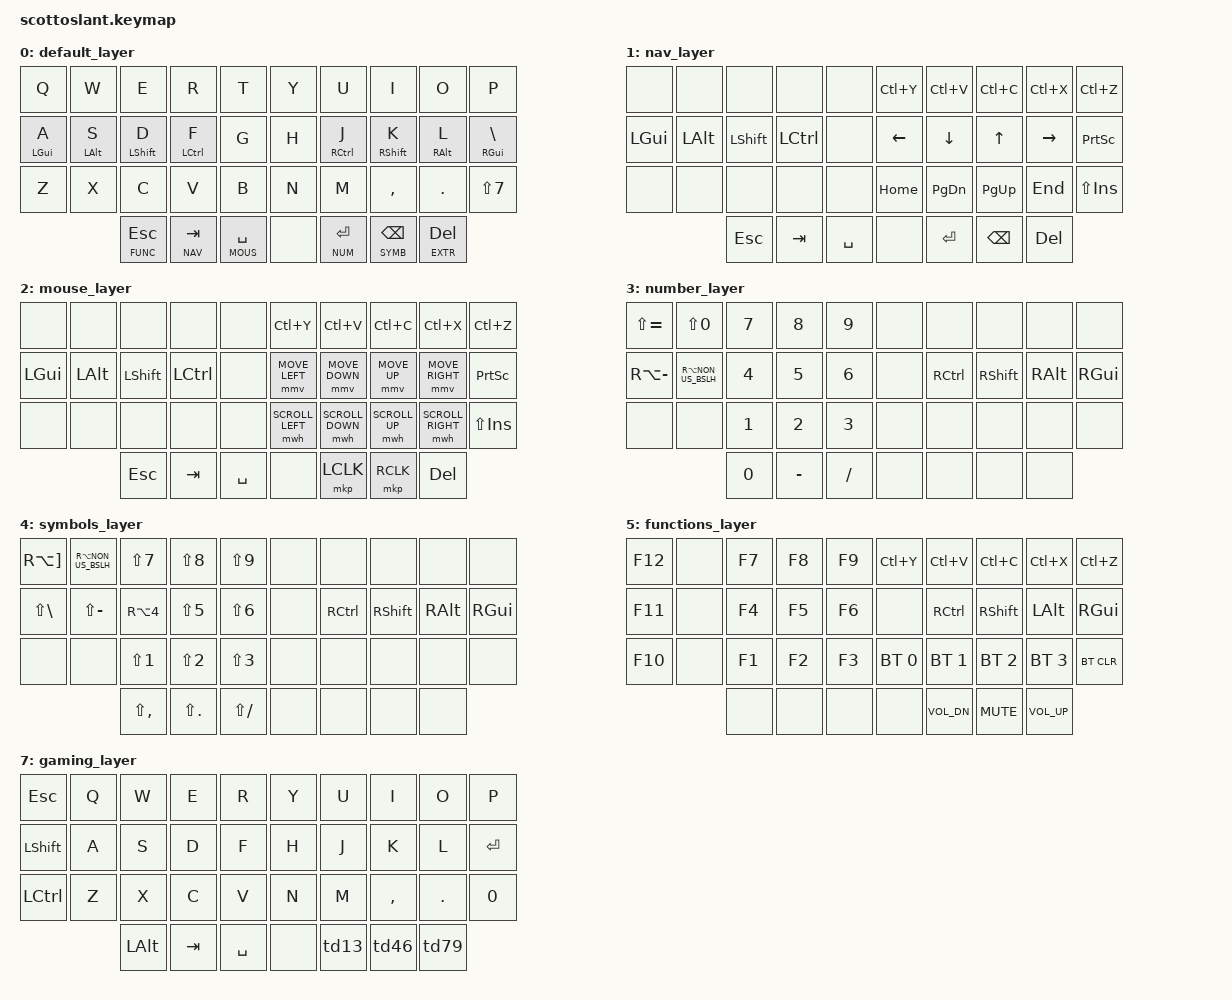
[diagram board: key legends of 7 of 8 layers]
#include <behaviors.dtsi>
#include <dt-bindings/zmk/keys.h>
#include <dt-bindings/zmk/bt.h>
#include <dt-bindings/zmk/mouse.h>

#define BASE 0
#define NAV 1
#define MOUS 2
#define NUM 3
#define SYMB 4
#define FUNC 5
#define EXTR 6
#define GAME 7

#define U_MOUSE_MOVE_MAX 1500
#define U_MOUSE_SCROLL_MAX 100

#undef MOVE_UP
#undef MOVE_DOWN
#undef MOVE_LEFT
#undef MOVE_RIGHT
#define MOVE_UP MOVE_VERT(-U_MOUSE_MOVE_MAX)
#define MOVE_DOWN MOVE_VERT(U_MOUSE_MOVE_MAX)
#define MOVE_LEFT MOVE_HOR(-U_MOUSE_MOVE_MAX)
#define MOVE_RIGHT MOVE_HOR(U_MOUSE_MOVE_MAX)

#undef SCROLL_UP
#undef SCROLL_DOWN
#undef SCROLL_LEFT
#undef SCROLL_RIGHT
#define SCROLL_UP SCROLL_VERT(U_MOUSE_SCROLL_MAX)
#define SCROLL_DOWN SCROLL_VERT(-U_MOUSE_SCROLL_MAX)
#define SCROLL_LEFT SCROLL_HOR(-U_MOUSE_SCROLL_MAX)
#define SCROLL_RIGHT SCROLL_HOR(U_MOUSE_SCROLL_MAX)

#define PAUSE PAUSE_BREAK
#define BT_0 BT_SEL 0
#define BT_1 BT_SEL 1
#define BT_2 BT_SEL 2
#define BT_3 BT_SEL 3

&mmv {
  time-to-max-speed-ms = <300>;
};

&mwh {
  time-to-max-speed-ms = <600>;
};

&lt {
  tapping-term-ms = <180>;
  quick-tap-ms = <180>;
};

/ {
    combos {
      compatible = "zmk,combos";
      combo_ae {
          timeout-ms = <50>;
          key-positions = <28 29>;
          bindings = <&kp SQT>;
      };
      combo_oe {
          timeout-ms = <50>;
          key-positions = <27 28>;
          bindings = <&kp SEMI>;
     };
      combo_ao {
          timeout-ms = <50>;
          key-positions = <26 27>;
          bindings = <&kp LBKT>;
      };
      combo_hard {
          timeout-ms = <50>;
          key-positions = <25 26>;
          bindings = <&kp RBKT>;
      };
      combo_game {
          timeout-ms = <50>;
          key-positions = <0 1 2>;
          bindings = <&tog GAME>;
          layers = <0 7>;
      };
    };
    behaviours {
     td13: num_dance_0 {
        compatible = "zmk,behavior-tap-dance";
        label = "TAP_DANCE_NUM_1_3";
        #binding-cells = <0>;
        tapping-term-ms = <200>;
        bindings = <&kp N1>, <&kp N2>, <&kp N3>;
      };
     td46: num_dance_1 {
        compatible = "zmk,behavior-tap-dance";
        label = "TAP_DANCE_NUM_4_6";
        #binding-cells = <0>;
        tapping-term-ms = <200>;
        bindings = <&kp N4>, <&kp N5>, <&kp N6>;
      };
     td79: num_dance_2 {
        compatible = "zmk,behavior-tap-dance";
        label = "TAP_DANCE_NUM_7_9";
        #binding-cells = <0>;
        tapping-term-ms = <200>;
        bindings = <&kp N7>, <&kp N8>, <&kp N9>;
      };
      hm: homerow_mods {
        compatible = "zmk,behavior-hold-tap";
        label = "HOMEROW_MODS";
        #binding-cells = <2>;
        tapping-term-ms = <180>;
        quick-tap-ms = <180>;
        flavor = "tap-preferred";
        bindings = <&kp>, <&kp>;
      };
     shm: shift_homerow_mods {
        compatible = "zmk,behavior-hold-tap";
        label = "SHIFT_HOMEROW_MODS";
        #binding-cells = <2>;
        tapping-term-ms = <180>;
        quick-tap-ms = <180>;
        flavor = "balanced";
        bindings = <&kp>, <&kp>;
      };
    };

    keymap {
        compatible = "zmk,keymap";

        default_layer {
            bindings = <
                &kp Q       &kp W       &kp E        &kp R       &kp T          &kp Y         &kp U         &kp I        &kp O      &kp P
                &hm LGUI A  &hm LALT S  &shm LSHFT D &hm LCTRL F &kp G          &kp H         &hm RCTRL J   &shm RSHFT K &hm RALT L &hm RGUI BSLH
                &kp Z       &kp X       &kp C        &kp V       &kp B          &kp N         &kp M         &kp COMMA    &kp DOT    &kp LS(N7)
                                        &lt FUNC ESC &lt NAV TAB &lt MOUS SPACE &none &lt NUM ENTER &lt SYMB BSPC &lt EXTR DEL

            >;
        };

        nav_layer {
            bindings = <
                &none       &none       &none       &none       &none       &kp LC(Y)   &kp LC(V)   &kp LC(C)   &kp LC(X)   &kp LC(Z)
                &kp LGUI    &kp LALT    &kp LSHFT   &kp LCTRL   &none       &kp LEFT    &kp DOWN    &kp UP      &kp RIGHT   &kp PSCRN
                &none       &none       &none       &none       &none       &kp HOME    &kp PG_DN   &kp PG_UP   &kp END     &kp LS(INSERT)
                                        &kp ESC     &kp TAB     &kp SPC     &none &kp ENTER   &kp BSPC    &kp DEL

            >;
        };

        mouse_layer {
            bindings = <
                &none       &none       &none       &none       &none   &kp LC(Y)        &kp LC(V)        &kp LC(C)       &kp LC(X)         &kp LC(Z)
                &kp LGUI    &kp LALT    &kp LSHFT   &kp LCTRL   &none   &mmv MOVE_LEFT   &mmv MOVE_DOWN   &mmv MOVE_UP    &mmv MOVE_RIGHT   &kp PSCRN
                &none       &none       &none       &none       &none   &mwh SCROLL_LEFT &mwh SCROLL_DOWN &mwh SCROLL_UP  &mwh SCROLL_RIGHT &kp LS(INSERT)
                                        &kp ESC     &kp TAB     &kp SPC  &none &mkp LCLK        &mkp RCLK        &kp DEL

            >;
        };

        number_layer {
            bindings = <
                &kp LS(EQUAL) &kp LS(N0)          &kp N7   &kp N8      &kp N9     &none  &none       &none       &none       &none
                &kp RA(MINUS) &kp RA(NON_US_BSLH) &kp N4   &kp N5      &kp N6     &none  &kp RCTRL   &kp RSHFT   &kp RALT    &kp RGUI
                &none         &none               &kp N1   &kp N2      &kp N3     &none  &none       &none       &none       &none
                                                  &kp N0   &kp MINUS   &kp SLASH  &none &none  &none       &none

            >;
        };

        symbols_layer {
            bindings = <
                &kp RA(RBKT)  &kp RA(NON_US_BSLH) &kp LS(N7)     &kp LS(N8)   &kp LS(N9)     &none  &none      &none      &none     &none
                &kp LS(BSLH)  &kp LS(MINUS)       &kp RA(N4)     &kp LS(N5)   &kp LS(N6)     &none  &kp RCTRL  &kp RSHFT  &kp RALT  &kp RGUI
                &none         &none               &kp LS(N1)     &kp LS(N2)   &kp LS(N3)     &none  &none      &none      &none     &none
                                                       &kp LS(COMMA)  &kp LS(DOT)  &kp LS(SLASH) &none &none  &none      &none

            >;
        };

        functions_layer {
            bindings = <
                &kp F12  &none   &kp F7   &kp F8   &kp F9   &kp LC(Y)    &kp LC(V)   &kp LC(C)   &kp LC(X)   &kp LC(Z)
                &kp F11  &none   &kp F4   &kp F5   &kp F6   &none        &kp RCTRL   &kp RSHFT   &kp LALT    &kp RGUI
                &kp F10  &none   &kp F1   &kp F2   &kp F3   &bt BT_0     &bt BT_1    &bt BT_2    &bt BT_3    &bt BT_CLR
                                 &none    &none    &none   &none &kp C_VOL_DN &kp C_MUTE  &kp C_VOL_UP

            >;
        };

        extras_layer {
            bindings = <
                &kp NON_US_BSLH &kp LS(NON_US_BSLH) &kp RA(NON_US_BSLH) &kp RA(N6)   &none   &none  &none     &none     &none    &kp CAPS
                &kp RA(N7)      &kp RA(N0)          &kp RA(N3)          &kp RA(N5)   &none   &none  &kp RCTRL &kp RSHFT &kp RALT &kp RGUI
                &kp RA(N8)      &kp RA(N9)          &kp RA(TILDE)       &kp RA(N2)   &none   &none  &none     &none     &none    &none
                                                    &kp LS(N8)          &kp LS(N9)   &none   &none &none  &none     &none     &none

            >;
        };

        gaming_layer {
            bindings = <
            &kp ESC     &kp Q    &kp W    &kp E   &kp R     &kp Y  &kp U  &kp I     &kp O   &kp P
            &kp LSHFT   &kp A    &kp S    &kp D   &kp F     &kp H  &kp J  &kp K     &kp L   &kp ENTER
            &kp LCTRL   &kp Z    &kp X    &kp C   &kp V     &kp N  &kp M  &kp COMMA &kp DOT &kp N0
                                 &kp LALT &kp TAB &kp SPACE &none &td13  &td46  &td79

            >;
        };
    };
};
